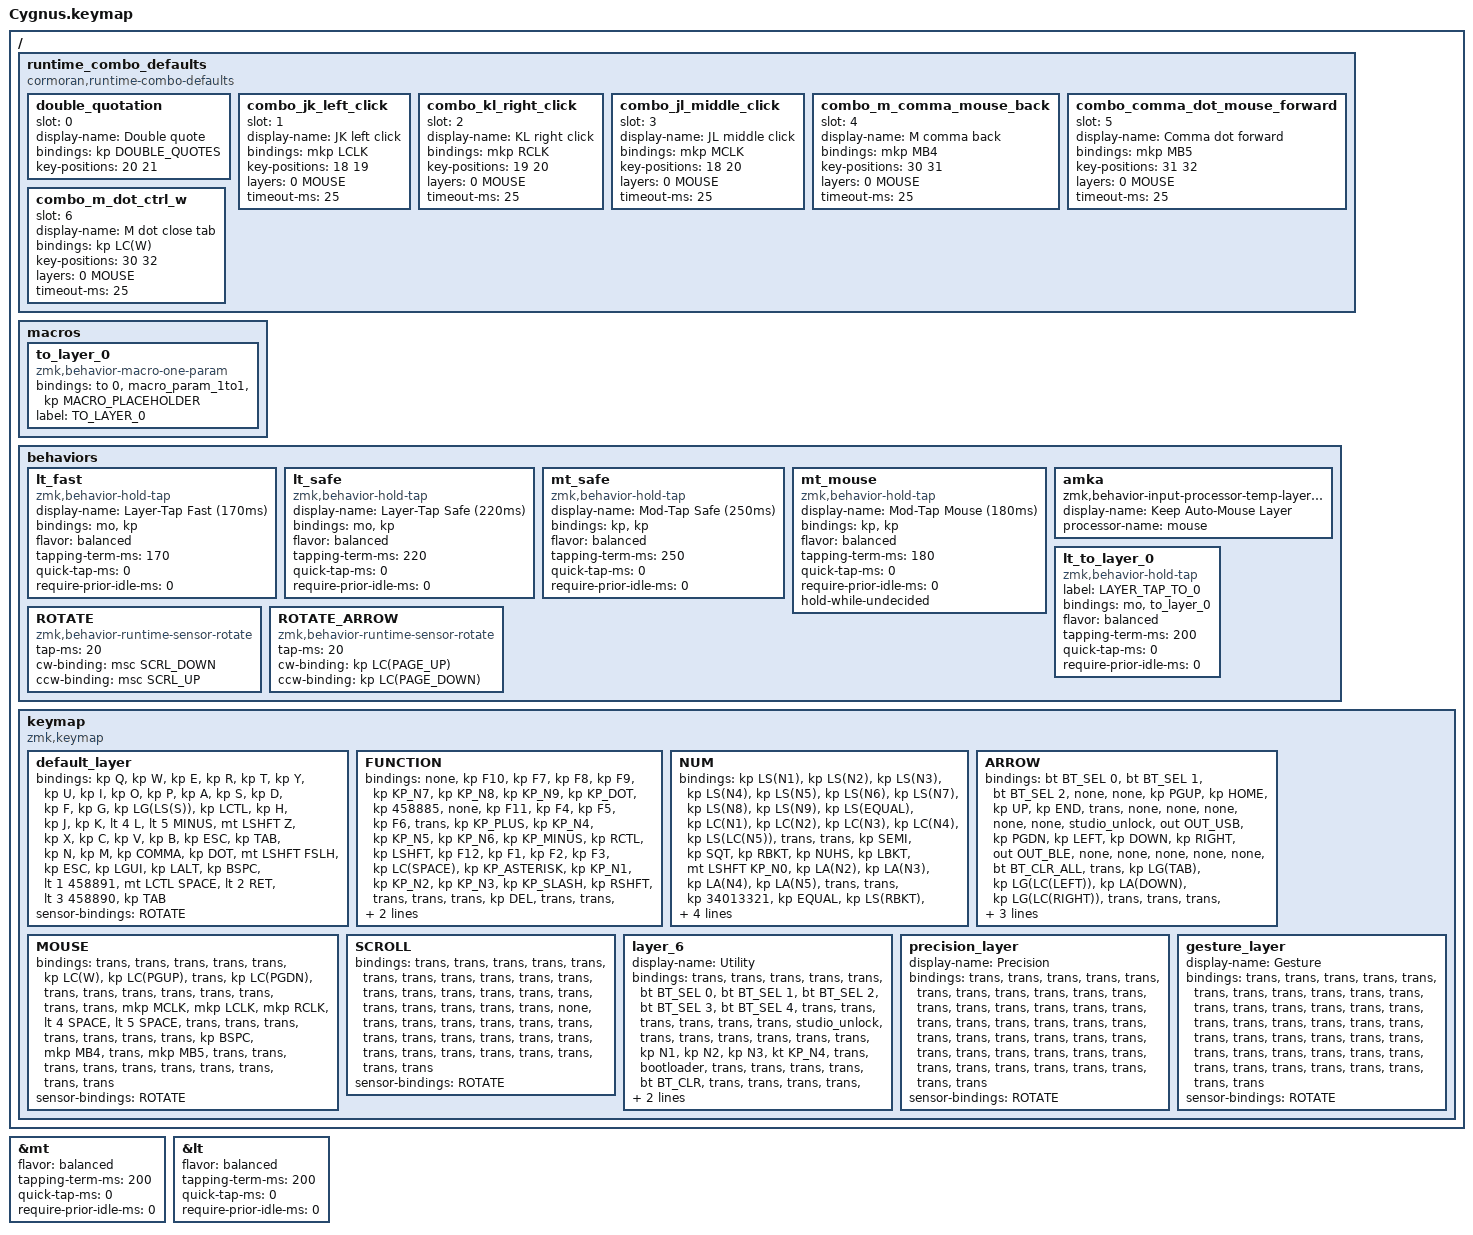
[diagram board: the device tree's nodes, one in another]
#define ZMK_POINTING_DEFAULT_SCRL_VAL 120    // default: 10

#include <behaviors.dtsi>
#include <behaviors/runtime-sensor-rotate.dtsi>
#include <behaviors/runtime_macro.dtsi>
#include <dt-bindings/zmk/bt.h>
#include <dt-bindings/zmk/keys.h>
#include <dt-bindings/zmk/outputs.h>
#include <dt-bindings/zmk/pointing.h>

#define MOUSE 4
#define SCROLL 5
#define NUM 6
#define PRECISION 7
#define GESTURE 8

&mt {
    flavor = "balanced";
    tapping-term-ms = <200>;
    quick-tap-ms = <0>;
    require-prior-idle-ms = <0>;
};

&lt {
    flavor = "balanced";
    tapping-term-ms = <200>;
    quick-tap-ms = <0>;
    require-prior-idle-ms = <0>;
};

/ {
    runtime_combo_defaults {
        compatible = "cormoran,runtime-combo-defaults";

        double_quotation {
            slot = <0>;
            display-name = "Double quote";
            bindings = <&kp DOUBLE_QUOTES>;
            key-positions = <20 21>;
        };

        combo_jk_left_click {
            slot = <1>;
            display-name = "JK left click";
            bindings = <&mkp LCLK>;
            key-positions = <18 19>;
            layers = <0 MOUSE>;
            timeout-ms = <25>;
        };

        combo_kl_right_click {
            slot = <2>;
            display-name = "KL right click";
            bindings = <&mkp RCLK>;
            key-positions = <19 20>;
            layers = <0 MOUSE>;
            timeout-ms = <25>;
        };

        combo_jl_middle_click {
            slot = <3>;
            display-name = "JL middle click";
            bindings = <&mkp MCLK>;
            key-positions = <18 20>;
            layers = <0 MOUSE>;
            timeout-ms = <25>;
        };

        combo_m_comma_mouse_back {
            slot = <4>;
            display-name = "M comma back";
            bindings = <&mkp MB4>;
            key-positions = <30 31>;
            layers = <0 MOUSE>;
            timeout-ms = <25>;
        };

        combo_comma_dot_mouse_forward {
            slot = <5>;
            display-name = "Comma dot forward";
            bindings = <&mkp MB5>;
            key-positions = <31 32>;
            layers = <0 MOUSE>;
            timeout-ms = <25>;
        };

        combo_m_dot_ctrl_w {
            slot = <6>;
            display-name = "M dot close tab";
            bindings = <&kp LC(W)>;
            key-positions = <30 32>;
            layers = <0 MOUSE>;
            timeout-ms = <25>;
        };
    };

    macros {
        to_layer_0: to_layer_0 {
            compatible = "zmk,behavior-macro-one-param";
            #binding-cells = <1>;
            bindings = <&to 0 &macro_param_1to1 &kp MACRO_PLACEHOLDER>;
            label = "TO_LAYER_0";
        };
    };

    behaviors {
        lt_fast: lt_fast {
            compatible = "zmk,behavior-hold-tap";
            display-name = "Layer-Tap Fast (170ms)";
            bindings = <&mo>, <&kp>;
            #binding-cells = <2>;
            flavor = "balanced";
            tapping-term-ms = <170>;
            quick-tap-ms = <0>;
            require-prior-idle-ms = <0>;
        };

        lt_safe: lt_safe {
            compatible = "zmk,behavior-hold-tap";
            display-name = "Layer-Tap Safe (220ms)";
            bindings = <&mo>, <&kp>;
            #binding-cells = <2>;
            flavor = "balanced";
            tapping-term-ms = <220>;
            quick-tap-ms = <0>;
            require-prior-idle-ms = <0>;
        };

        mt_safe: mt_safe {
            compatible = "zmk,behavior-hold-tap";
            display-name = "Mod-Tap Safe (250ms)";
            bindings = <&kp>, <&kp>;
            #binding-cells = <2>;
            flavor = "balanced";
            tapping-term-ms = <250>;
            quick-tap-ms = <0>;
            require-prior-idle-ms = <0>;
        };

        mt_mouse: mt_mouse {
            compatible = "zmk,behavior-hold-tap";
            display-name = "Mod-Tap Mouse (180ms)";
            bindings = <&kp>, <&kp>;
            #binding-cells = <2>;
            flavor = "balanced";
            tapping-term-ms = <180>;
            quick-tap-ms = <0>;
            require-prior-idle-ms = <0>;
            hold-while-undecided;
        };

        amka: amka {
            compatible = "zmk,behavior-input-processor-temp-layer-keep-active";
            display-name = "Keep Auto-Mouse Layer";
            processor-name = "mouse";
            #binding-cells = <0>;
        };

        lt_to_layer_0: lt_to_layer_0 {
            compatible = "zmk,behavior-hold-tap";
            label = "LAYER_TAP_TO_0";
            bindings = <&mo>, <&to_layer_0>;

            #binding-cells = <2>;
            flavor = "balanced";
            tapping-term-ms = <200>;
            quick-tap-ms = <0>;
            require-prior-idle-ms = <0>;
        };

        ROTATE: ROTATE {
            compatible = "zmk,behavior-runtime-sensor-rotate";
            #sensor-binding-cells = <0>;
            tap-ms = <20>;
            cw-binding = <&msc SCRL_DOWN>;
            ccw-binding = <&msc SCRL_UP>;
        };

        ROTATE_ARROW: ROTATE_ARROW {
            compatible = "zmk,behavior-runtime-sensor-rotate";
            #sensor-binding-cells = <0>;
            tap-ms = <20>;
            cw-binding = <&kp LC(PAGE_UP)>;
            ccw-binding = <&kp LC(PAGE_DOWN)>;
        };
    };

    keymap {
        compatible = "zmk,keymap";

        default_layer {
            bindings = <
                &kp Q
                &kp W
                &kp E
                &kp R
                &kp T
                &kp Y
                &kp U
                &kp I
                &kp O
                &kp P
                &kp A
                &kp S
                &kp D
                &kp F
                &kp G
                &kp LG(LS(S))
                &kp LCTL
                &kp H
                &kp J
                &kp K
                &lt 4 L
                &lt 5 MINUS
                &mt LSHFT Z
                &kp X
                &kp C
                &kp V
                &kp B
                &kp ESC
                &kp TAB
                &kp N
                &kp M
                &kp COMMA
                &kp DOT
                &mt LSHFT FSLH
                &kp ESC
                &kp LGUI
                &kp LALT
                &kp BSPC
                &lt 1 458891
                &mt LCTL SPACE
                &lt 2 RET
                &lt 3 458890
                &kp TAB
            >;

            sensor-bindings = <&ROTATE>;
        };

        FUNCTION {
            bindings = <
                &none
                &kp F10
                &kp F7
                &kp F8
                &kp F9
                &kp KP_N7
                &kp KP_N8
                &kp KP_N9
                &kp KP_DOT
                &kp 458885
                &none
                &kp F11
                &kp F4
                &kp F5
                &kp F6
                &trans
                &kp KP_PLUS
                &kp KP_N4
                &kp KP_N5
                &kp KP_N6
                &kp KP_MINUS
                &kp RCTL
                &kp LSHFT
                &kp F12
                &kp F1
                &kp F2
                &kp F3
                &kp LC(SPACE)
                &kp KP_ASTERISK
                &kp KP_N1
                &kp KP_N2
                &kp KP_N3
                &kp KP_SLASH
                &kp RSHFT
                &trans
                &trans
                &trans
                &kp DEL
                &trans
                &trans
                &kp KP_DOT
                &kp KP_N0
                &kp COMMA
            >;

            sensor-bindings = <&ROTATE>;
        };

        NUM {
            bindings = <
                &kp LS(N1)
                &kp LS(N2)
                &kp LS(N3)
                &kp LS(N4)
                &kp LS(N5)
                &kp LS(N6)
                &kp LS(N7)
                &kp LS(N8)
                &kp LS(N9)
                &kp LS(EQUAL)
                &kp LC(N1)
                &kp LC(N2)
                &kp LC(N3)
                &kp LC(N4)
                &kp LS(LC(N5))
                &trans
                &trans
                &kp SEMI
                &kp SQT
                &kp RBKT
                &kp NUHS
                &kp LBKT
                &mt LSHFT KP_N0
                &kp LA(N2)
                &kp LA(N3)
                &kp LA(N4)
                &kp LA(N5)
                &trans
                &trans
                &kp 34013321
                &kp EQUAL
                &kp LS(RBKT)
                &kp LS(NUHS)
                &mt RSHFT 34013319
                &kp LG(N1)
                &kp LG(N2)
                &kp LG(N3)
                &kp DEL
                &trans
                &trans
                &trans
                &trans
                &kp 458887
            >;

            sensor-bindings = <&ROTATE>;
        };

        ARROW {
            bindings = <
                &bt BT_SEL 0
                &bt BT_SEL 1
                &bt BT_SEL 2
                &none
                &none
                &kp PGUP
                &kp HOME
                &kp UP
                &kp END
                &trans
                &none
                &none
                &none
                &none
                &none
                &studio_unlock
                &out OUT_USB
                &kp PGDN
                &kp LEFT
                &kp DOWN
                &kp RIGHT
                &out OUT_BLE
                &none
                &none
                &none
                &none
                &none
                &bt BT_CLR_ALL
                &trans
                &kp LG(TAB)
                &kp LG(LC(LEFT))
                &kp LA(DOWN)
                &kp LG(LC(RIGHT))
                &trans
                &trans
                &trans
                &trans
                &kp DEL
                &kp LSHFT
                &trans
                &trans
                &trans
                &trans
            >;

            sensor-bindings = <&ROTATE_ARROW>;
        };

        MOUSE {
            bindings = <
                &trans
                &trans
                &trans
                &trans
                &trans
                &kp LC(W)
                &kp LC(PGUP)
                &trans
                &kp LC(PGDN)
                &trans
                &trans
                &trans
                &trans
                &trans
                &trans
                &trans
                &trans
                &mkp MCLK
                &mkp LCLK
                &mkp RCLK
                &lt 4 SPACE
                &lt 5 SPACE
                &trans
                &trans
                &trans
                &trans
                &trans
                &trans
                &trans
                &kp BSPC
                &mkp MB4
                &trans
                &mkp MB5
                &trans
                &trans
                &trans
                &trans
                &trans
                &trans
                &trans
                &trans
                &trans
                &trans
            >;

            sensor-bindings = <&ROTATE>;
        };

        SCROLL {
            bindings = <
                &trans
                &trans
                &trans
                &trans
                &trans
                &trans
                &trans
                &trans
                &trans
                &trans
                &trans
                &trans
                &trans
                &trans
                &trans
                &trans
                &trans
                &trans
                &trans
                &trans
                &trans
                &trans
                &none
                &trans
                &trans
                &trans
                &trans
                &trans
                &trans
                &trans
                &trans
                &trans
                &trans
                &trans
                &trans
                &trans
                &trans
                &trans
                &trans
                &trans
                &trans
                &trans
                &trans
            >;

            sensor-bindings = <&ROTATE>;
        };

        layer_6 {
            display-name = "Utility";
            bindings = <
                &trans
                &trans
                &trans
                &trans
                &trans
                &bt BT_SEL 0
                &bt BT_SEL 1
                &bt BT_SEL 2
                &bt BT_SEL 3
                &bt BT_SEL 4
                &trans
                &trans
                &trans
                &trans
                &trans
                &trans
                &studio_unlock
                &trans
                &trans
                &trans
                &trans
                &trans
                &trans
                &kp N1
                &kp N2
                &kp N3
                &kt KP_N4
                &trans
                &bootloader
                &trans
                &trans
                &trans
                &trans
                &bt BT_CLR
                &trans
                &trans
                &trans
                &trans
                &trans
                &trans
                &trans
                &trans
                &bt BT_CLR_ALL
            >;

            sensor-bindings = <&ROTATE>;
        };

        precision_layer {
            display-name = "Precision";
            bindings = <
                &trans
                &trans
                &trans
                &trans
                &trans
                &trans
                &trans
                &trans
                &trans
                &trans
                &trans
                &trans
                &trans
                &trans
                &trans
                &trans
                &trans
                &trans
                &trans
                &trans
                &trans
                &trans
                &trans
                &trans
                &trans
                &trans
                &trans
                &trans
                &trans
                &trans
                &trans
                &trans
                &trans
                &trans
                &trans
                &trans
                &trans
                &trans
                &trans
                &trans
                &trans
                &trans
                &trans
            >;

            sensor-bindings = <&ROTATE>;
        };

        gesture_layer {
            display-name = "Gesture";
            bindings = <
                &trans
                &trans
                &trans
                &trans
                &trans
                &trans
                &trans
                &trans
                &trans
                &trans
                &trans
                &trans
                &trans
                &trans
                &trans
                &trans
                &trans
                &trans
                &trans
                &trans
                &trans
                &trans
                &trans
                &trans
                &trans
                &trans
                &trans
                &trans
                &trans
                &trans
                &trans
                &trans
                &trans
                &trans
                &trans
                &trans
                &trans
                &trans
                &trans
                &trans
                &trans
                &trans
                &trans
            >;

            sensor-bindings = <&ROTATE>;
        };
    };
};
